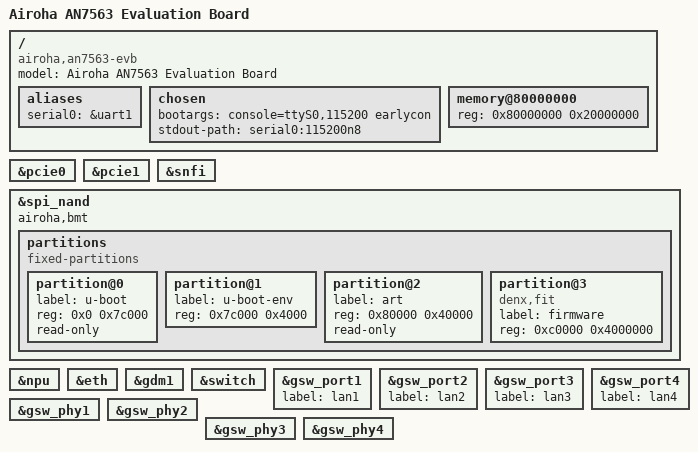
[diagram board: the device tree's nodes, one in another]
// SPDX-License-Identifier: (GPL-2.0-only OR BSD-2-Clause)
/dts-v1/;

/* Bootloader installs ATF here (BL31 resident region, ~256 KiB). */
/memreserve/ 0x80000000 0x88000;

#include <dt-bindings/leds/common.h>
#include <dt-bindings/gpio/gpio.h>
#include <dt-bindings/input/input.h>
#include "an7563.dtsi"

/ {
	model = "Airoha AN7563 Evaluation Board";
	compatible = "airoha,an7563-evb", "airoha,an7563", "airoha,en7581";

	aliases {
		serial0 = &uart1;
	};

	chosen {
		bootargs = "console=ttyS0,115200 earlycon";
		stdout-path = "serial0:115200n8";
	};

	memory@80000000 {
		device_type = "memory";
		reg = <0x80000000 0x20000000>;
	};
};

&pcie0 {
	status = "okay";
};

&pcie1 {
	status = "okay";
};

&snfi {
	status = "okay";
};

&spi_nand {
	airoha,bmt;

	partitions {
		compatible = "fixed-partitions";
		#address-cells = <1>;
		#size-cells = <1>;

		partition@0 {
			label = "u-boot";
			reg = <0x0 0x7c000>;
			read-only;
		};

		partition@1 {
			label = "u-boot-env";
			reg = <0x7c000 0x4000>;
		};

		partition@2 {
			label = "art";
			reg = <0x80000 0x40000>;
			read-only;
		};

		partition@3 {
			compatible = "denx,fit";
			label = "firmware";
			reg = <0xc0000 0x4000000>;
		};
	};
};

/*
 * Ethernet bring-up: AN7563 RFB and Xiaomi BE5000 both use the on-chip
 * 5-port Gigabit Switch behind GDM1; neither board wires an external
 * AN8811H 2.5G PHY (BE5000 reaches the 2.5G uplink through the XPON
 * stack, RFB has no uplink PHY). The eth / qdma / mdio / gsw_phy
 * skeleton lives in an7563.dtsi - enable here per board.
 *
 * This re-enable goes together with patch 611-net-airoha-add-AN7563-
 * eth-soc-data-and-init-probes which adds a dedicated
 * "airoha,an7563-eth" SoC data (num_ppe=1, since AN7563 silicon only
 * exposes a 2-core NPU / single PPE engine instead of EN7581's
 * 8-core NPU / dual PPE) plus dev_info traces in every init phase,
 * so a follow-up panic - if any - can be pinned down to a specific
 * step instead of just "somewhere in airoha_probe".
 */
&npu {
	status = "okay";
};

&eth {
	status = "okay";
};

&gdm1 {
	status = "okay";
};

&switch {
	status = "okay";
};

&gsw_port1 {
	label = "lan1";
	status = "okay";
};

&gsw_port2 {
	label = "lan2";
	status = "okay";
};

&gsw_port3 {
	label = "lan3";
	status = "okay";
};

&gsw_port4 {
	label = "lan4";
	status = "okay";
};

&gsw_phy1 {
	status = "okay";
};

&gsw_phy2 {
	status = "okay";
};

&gsw_phy3 {
	status = "okay";
};

&gsw_phy4 {
	status = "okay";
};
